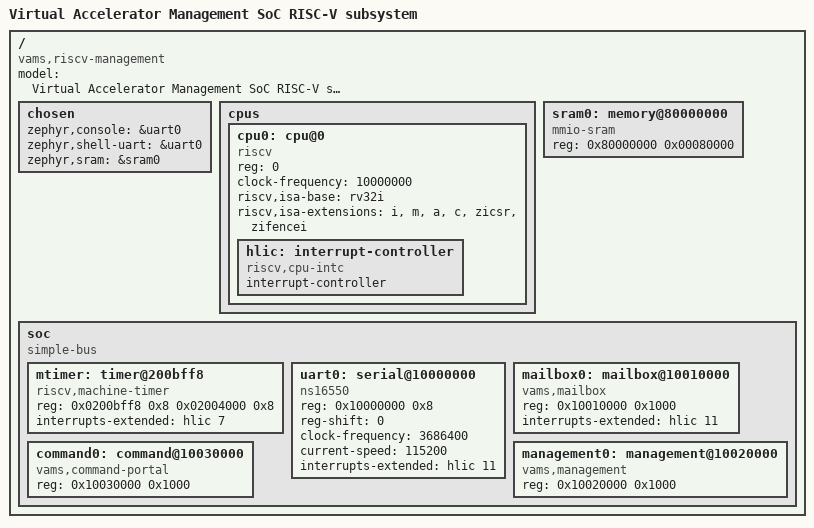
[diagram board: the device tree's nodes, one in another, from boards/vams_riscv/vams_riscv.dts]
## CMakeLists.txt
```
# SPDX-License-Identifier: MIT

cmake_minimum_required(VERSION 3.20.0)
find_package(Zephyr REQUIRED HINTS $ENV{ZEPHYR_BASE})
project(vams_management_firmware)

target_include_directories(app PRIVATE include)
target_sources(app PRIVATE
  src/main.c
  src/command/vams_command.c
  src/health/vams_health.c
  src/logging/vams_event.c
  src/recovery/vams_retained.c
  src/scheduler/vams_scheduler.c
  drivers/vams_command_portal.c
  drivers/vams_mailbox.c
  drivers/vams_management.c
)

# Zephyr's RISC-V linker flow uses OMAGIC for a RAM-only image. Binutils 2.39+
# diagnoses the resulting load segment; the SRAM is intentionally executable
# and writable on this management subsystem.
target_link_options(app PUBLIC -Wl,--no-warn-rwx-segments)
```

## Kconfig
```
# SPDX-License-Identifier: MIT

mainmenu "VAMS management firmware"

source "Kconfig.zephyr"

config VAMS_WATCHDOG_EXPIRY_TEST
	bool "Deliberately allow the first watchdog deadline to expire"
	default n
	help
	  Exercise watchdog recovery by withholding pets until the first
	  watchdog-initiated management reset has completed.

config VAMS_SCHEDULER_TEST_DELAY_MS
	int "Test-only delay before scheduler dispatch"
	default 0
	range 0 1000
	help
	  Delay dispatch to exercise deterministic queued-command expiry. Keep
	  this zero in the normal firmware configuration.

config VAMS_OVERLOAD_TEST
	bool "Inject deterministic diagnostic queue pressure"
	default n
	help
	  Fill the bounded event and heartbeat queues before their consumers
	  start so the overload counters and nonblocking drop policy can be
	  validated. Keep this disabled in the normal firmware configuration.

config VAMS_HEALTH_TEST
	bool "Honor the model's test-only task freeze selector"
	default n
	help
	  Freeze one selected essential task on the first boot so per-task health
	  diagnosis and watchdog recovery can be tested. The selector is ignored
	  in normal firmware builds.
```

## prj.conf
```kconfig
CONFIG_PRINTK=y
CONFIG_BOOT_BANNER=n
CONFIG_COMPILER_WARNINGS_AS_ERRORS=y
CONFIG_ASSERT=y
CONFIG_THREAD_NAME=y
CONFIG_THREAD_STACK_INFO=y
CONFIG_INIT_STACKS=y
CONFIG_STACK_SENTINEL=y
CONFIG_MAIN_STACK_SIZE=1024
CONFIG_ISR_STACK_SIZE=1024
CONFIG_IDLE_STACK_SIZE=512
```

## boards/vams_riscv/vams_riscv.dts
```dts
/* SPDX-License-Identifier: MIT */

/dts-v1/;

/ {
	model = "Virtual Accelerator Management SoC RISC-V subsystem";
	compatible = "vams,riscv-management";
	#address-cells = <1>;
	#size-cells = <1>;

	chosen {
		zephyr,console = &uart0;
		zephyr,shell-uart = &uart0;
		zephyr,sram = &sram0;
	};

	cpus {
		#address-cells = <1>;
		#size-cells = <0>;

		cpu0: cpu@0 {
			compatible = "riscv";
			device_type = "cpu";
			reg = <0>;
			clock-frequency = <10000000>;
			riscv,isa-base = "rv32i";
			riscv,isa-extensions = "i", "m", "a", "c", "zicsr", "zifencei";
			status = "okay";

			hlic: interrupt-controller {
				compatible = "riscv,cpu-intc";
				#address-cells = <0>;
				#interrupt-cells = <1>;
				interrupt-controller;
			};
		};
	};

	sram0: memory@80000000 {
		compatible = "mmio-sram";
		device_type = "memory";
		reg = <0x80000000 0x00080000>;
	};

	soc {
		compatible = "simple-bus";
		#address-cells = <1>;
		#size-cells = <1>;
		ranges;

		mtimer: timer@200bff8 {
			compatible = "riscv,machine-timer";
			reg = <0x0200bff8 0x8 0x02004000 0x8>;
			reg-names = "mtime", "mtimecmp";
			interrupts-extended = <&hlic 7>;
			status = "okay";
		};

		uart0: serial@10000000 {
			compatible = "ns16550";
			reg = <0x10000000 0x8>;
			reg-shift = <0>;
			clock-frequency = <3686400>;
			current-speed = <115200>;
			interrupts-extended = <&hlic 11>;
			status = "okay";
		};

		mailbox0: mailbox@10010000 {
			compatible = "vams,mailbox";
			reg = <0x10010000 0x1000>;
			interrupts-extended = <&hlic 11>;
			status = "okay";
		};

		management0: management@10020000 {
			compatible = "vams,management";
			reg = <0x10020000 0x1000>;
			status = "okay";
		};

		command0: command@10030000 {
			compatible = "vams,command-portal";
			reg = <0x10030000 0x1000>;
			status = "okay";
		};
	};
};
```

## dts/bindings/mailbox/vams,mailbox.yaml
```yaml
description: VAMS host-to-firmware mailbox

compatible: "vams,mailbox"

include: base.yaml

properties:
  reg:
    required: true

  interrupts-extended:
    required: true
```

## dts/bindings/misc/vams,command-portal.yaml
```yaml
description: VAMS private firmware command portal

compatible: "vams,command-portal"

include: base.yaml

properties:
  reg:
    required: true
```

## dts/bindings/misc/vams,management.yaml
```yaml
description: VAMS watchdog, reset, and telemetry registers

compatible: "vams,management"

include: base.yaml

properties:
  reg:
    required: true
```

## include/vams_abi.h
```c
/* SPDX-License-Identifier: MIT */
/* Generated by scripts/gen-vams-abi.py; do not edit. */
#ifndef VAMS_FIRMWARE_ABI_H
#define VAMS_FIRMWARE_ABI_H

#include <stdint.h>

#define VAMS_DESC_VERSION_1 1U
#define VAMS_OP_NOP 0x0000U
#define VAMS_OP_MEM_COPY 0x0001U
#define VAMS_OP_MEM_FILL 0x0002U
#define VAMS_OP_CRC32 0x0003U
#define VAMS_OP_VECTOR_ADD 0x0004U
#define VAMS_SUB_F_VERIFY_CRC 0x0001U
#define VAMS_STATUS_SUCCESS 0x0000U
#define VAMS_STATUS_INVALID 0x0001U
#define VAMS_STATUS_FAILED 0x0002U
#define VAMS_STATUS_TIMED_OUT 0x0003U
#define VAMS_STATUS_CANCELLED 0x0004U
#define VAMS_STATUS_RESET 0x0005U
#define VAMS_ERR_NONE 0x0000U
#define VAMS_ERR_UNSUPPORTED_VERSION 0x0001U
#define VAMS_ERR_INVALID_OPCODE 0x0002U
#define VAMS_ERR_INVALID_FLAGS 0x0003U
#define VAMS_ERR_RESERVED_NONZERO 0x0004U
#define VAMS_ERR_DUPLICATE_ID 0x0005U
#define VAMS_ERR_INVALID_LENGTH 0x0006U
#define VAMS_ERR_INVALID_ALIGNMENT 0x0007U
#define VAMS_ERR_ADDRESS_OVERFLOW 0x0008U
#define VAMS_ERR_INVALID_ADDRESS 0x0009U
#define VAMS_ERR_INVALID_TIMEOUT 0x000aU
#define VAMS_ERR_DMA_READ 0x0010U
#define VAMS_ERR_DMA_WRITE 0x0011U
#define VAMS_ERR_ENGINE 0x0012U
#define VAMS_ERR_TIMEOUT 0x0013U
#define VAMS_ERR_CRC_MISMATCH 0x0014U
#define VAMS_ERR_RESET 0x0015U
#define VAMS_ERR_QUEUE_RESET 0x0016U
#define VAMS_ERR_DEVICE_FATAL 0x0017U

struct __attribute__((packed)) vams_submission {
    uint16_t version;
    uint8_t opcode;
    uint8_t flags;
    uint32_t command_id;
    uint64_t source_dma;
    uint64_t destination_dma;
    uint32_t length;
    uint32_t timeout_ms;
    uint64_t user_cookie;
    uint32_t expected_crc;
    uint32_t reserved0;
    uint64_t reserved1;
    uint64_t reserved2;
};

struct __attribute__((packed)) vams_completion {
    uint32_t command_id;
    uint16_t status;
    uint16_t error_code;
    uint32_t bytes_processed;
    uint32_t result_crc;
    uint64_t user_cookie;
    uint64_t device_timestamp;
};

#define VAMS_SUBMISSION_SIZE 64U
#define VAMS_COMPLETION_SIZE 32U

#endif /* VAMS_FIRMWARE_ABI_H */
```

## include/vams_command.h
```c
/* SPDX-License-Identifier: MIT */
#ifndef VAMS_COMMAND_H
#define VAMS_COMMAND_H

#include <stdint.h>

#include <vams_abi.h>

void vams_command_execute(const struct vams_submission *submission,
			  struct vams_completion *completion,
			  uint64_t timestamp);

#endif /* VAMS_COMMAND_H */
```

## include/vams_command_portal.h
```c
/* SPDX-License-Identifier: MIT */
#ifndef VAMS_COMMAND_PORTAL_H
#define VAMS_COMMAND_PORTAL_H

#include <zephyr/device.h>
#include <zephyr/kernel.h>

#include <vams_abi.h>

bool vams_command_pending(const struct device *dev);
int vams_command_receive(const struct device *dev,
			 struct vams_submission *submission,
			 k_timeout_t timeout);
int vams_command_complete(const struct device *dev,
			  const struct vams_completion *completion);
int vams_command_abort(const struct device *dev,
		       const struct vams_completion *request);
int vams_command_result_receive(const struct device *dev,
				struct vams_completion *result,
				k_timeout_t timeout);

#endif /* VAMS_COMMAND_PORTAL_H */
```

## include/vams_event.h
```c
/* SPDX-License-Identifier: MIT */
#ifndef VAMS_EVENT_H
#define VAMS_EVENT_H

#include <stdint.h>

#include <zephyr/kernel.h>

enum vams_event_id {
	VAMS_EVENT_TRANSITION = 1,
	VAMS_EVENT_PUBLISHED,
	VAMS_EVENT_HEARTBEAT,
	VAMS_EVENT_MAILBOX,
	VAMS_EVENT_ABORT_REQUEST,
	VAMS_EVENT_ABORT_ESCALATED,
	VAMS_EVENT_RESULT_MISMATCH,
	VAMS_EVENT_COMMAND_COMPLETE,
	VAMS_EVENT_TELEMETRY,
	VAMS_EVENT_WATCHDOG_WITHHELD,
	VAMS_EVENT_OVERLOAD_TEST,
	VAMS_EVENT_HEALTH_STUCK,
};

struct vams_event {
	uint64_t timestamp_ms;
	uint64_t value;
	uint32_t command_id;
	uint32_t generation;
	uint32_t arg0;
	uint32_t arg1;
	uint32_t arg2;
	uint16_t id;
	uint16_t reserved;
};

void vams_event_emit(enum vams_event_id id, uint32_t command_id,
		     uint32_t generation, uint32_t arg0, uint32_t arg1,
		     uint32_t arg2, uint64_t value);
int vams_event_receive(struct vams_event *event, k_timeout_t timeout);
uint32_t vams_event_drop_count(void);

#endif /* VAMS_EVENT_H */
```

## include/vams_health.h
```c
/* SPDX-License-Identifier: MIT */
#ifndef VAMS_HEALTH_H
#define VAMS_HEALTH_H

#include <stdbool.h>
#include <stdint.h>

#include <vams_overload.h>

enum vams_health_task_id {
	VAMS_HEALTH_TASK_NONE = 0,
	VAMS_HEALTH_TASK_PRODUCER = 1,
	VAMS_HEALTH_TASK_MONITOR = 2,
	VAMS_HEALTH_TASK_MAILBOX = 3,
	VAMS_HEALTH_TASK_RECEIVER = 4,
	VAMS_HEALTH_TASK_VALIDATOR = 5,
	VAMS_HEALTH_TASK_SCHEDULER = 6,
	VAMS_HEALTH_TASK_RECOVERY = 7,
	VAMS_HEALTH_TASK_COMPLETION = 8,
	VAMS_HEALTH_TASK_COUNT = 8,
};

struct vams_health_tracker {
	uint32_t last_epoch[VAMS_HEALTH_TASK_COUNT];
	uint32_t missed[VAMS_HEALTH_TASK_COUNT];
	uint32_t failure_count;
	uint32_t stuck_task;
	uint32_t startup_grace;
	uint32_t miss_limit;
	bool failure_latched;
};

void vams_health_tracker_init(struct vams_health_tracker *tracker,
			      const uint32_t epochs[VAMS_HEALTH_TASK_COUNT],
			      uint32_t startup_grace, uint32_t miss_limit);
bool vams_health_tracker_update(
	struct vams_health_tracker *tracker,
	const uint32_t epochs[VAMS_HEALTH_TASK_COUNT]);

#endif /* VAMS_HEALTH_H */
```

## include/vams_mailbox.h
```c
/* SPDX-License-Identifier: MIT */

#ifndef VAMS_MAILBOX_H
#define VAMS_MAILBOX_H

#include <stdint.h>

#include <zephyr/device.h>
#include <zephyr/kernel.h>

#define VAMS_MAILBOX_PING UINT32_C(0x00000001)
#define VAMS_MAILBOX_PING_RESPONSE UINT32_C(0x80000001)
#define VAMS_MAILBOX_UNSUPPORTED UINT32_C(0xffffffff)

int vams_mailbox_receive(const struct device *dev, uint32_t *message,
			 k_timeout_t timeout);
int vams_mailbox_respond(const struct device *dev, uint32_t response);

#endif /* VAMS_MAILBOX_H */
```

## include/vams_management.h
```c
/* SPDX-License-Identifier: MIT */

#ifndef VAMS_MANAGEMENT_H
#define VAMS_MANAGEMENT_H

#include <stdbool.h>
#include <stdint.h>

#include <zephyr/device.h>

#define VAMS_MANAGEMENT_RETENTION_SIZE 128U

#define VAMS_RESET_REASON_POWER_ON UINT32_C(0)
#define VAMS_RESET_REASON_FIRMWARE UINT32_C(4)
#define VAMS_RESET_REASON_WATCHDOG UINT32_C(5)

struct vams_management_snapshot {
	uint32_t reset_reason;
	uint32_t watchdog_reset_count;
	uint32_t reset_generation;
	uint32_t reset_notify_count;
	uint32_t reset_notify_fail_count;
	uint32_t reset_ack_count;
	uint32_t reset_ack_timeout_count;
	uint32_t reset_coalesce_count;
	uint32_t test_freeze_task;
	uint32_t mailbox_rx_count;
	uint32_t mailbox_tx_count;
	uint32_t status;
	bool watchdog_enabled;
};

int vams_management_watchdog_start(const struct device *dev,
				   uint32_t timeout_ms);
int vams_management_watchdog_pet(const struct device *dev);
void vams_management_publish(const struct device *dev, uint32_t heartbeat,
			     uint64_t uptime_ms, uint32_t firmware_version);
void vams_management_snapshot(const struct device *dev,
			      struct vams_management_snapshot *snapshot);
void vams_management_reset(const struct device *dev);
void vams_management_retention_read(const struct device *dev, void *data,
				    uint32_t length);
void vams_management_retention_write(const struct device *dev,
				     const void *data, uint32_t length);

#endif /* VAMS_MANAGEMENT_H */
```

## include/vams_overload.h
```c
/* SPDX-License-Identifier: MIT */
#ifndef VAMS_OVERLOAD_H
#define VAMS_OVERLOAD_H

#include <stdbool.h>
#include <stdint.h>

static inline uint32_t vams_counter_increment(uint32_t value)
{
	return value == UINT32_MAX ? UINT32_MAX : value + 1U;
}

static inline bool vams_command_admission_allowed(bool portal_pending,
						   uint32_t pool_free)
{
	return portal_pending && pool_free > 0U;
}

#endif /* VAMS_OVERLOAD_H */
```

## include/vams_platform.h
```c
/* SPDX-License-Identifier: MIT */
#ifndef VAMS_PLATFORM_H
#define VAMS_PLATFORM_H

#ifndef __ASSEMBLER__
#include <stdint.h>
#define VAMS_U32(value) UINT32_C(value)
#define VAMS_U8(value)  UINT8_C(value)
#else
#define VAMS_U32(value) value
#define VAMS_U8(value)  value
#endif

#define VAMS_ROM_BASE             VAMS_U32(0x00001000)
#define VAMS_ROM_SIZE             VAMS_U32(0x00010000)
#define VAMS_ACLINT_SWI_BASE      VAMS_U32(0x02000000)
#define VAMS_ACLINT_MTIMER_BASE   VAMS_U32(0x02004000)
#define VAMS_ACLINT_MTIMECMP      (VAMS_ACLINT_MTIMER_BASE + VAMS_U32(0x0000))
#define VAMS_ACLINT_MTIME         (VAMS_ACLINT_MTIMER_BASE + VAMS_U32(0x7ff8))
#define VAMS_UART_BASE            VAMS_U32(0x10000000)
#define VAMS_SRAM_BASE            VAMS_U32(0x80000000)
#define VAMS_SRAM_SIZE            VAMS_U32(0x00080000)

#define VAMS_UART_THR             VAMS_U32(0x0)
#define VAMS_UART_LSR             VAMS_U32(0x5)
#define VAMS_UART_LSR_THRE        VAMS_U8(0x20)

#define VAMS_MCAUSE_TIMER         VAMS_U32(0x80000007)
#define VAMS_MIE_MTIE             (VAMS_U32(1) << 7)
#define VAMS_MSTATUS_MIE          (VAMS_U32(1) << 3)

#endif
```

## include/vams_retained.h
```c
/* SPDX-License-Identifier: MIT */
#ifndef VAMS_RETAINED_H
#define VAMS_RETAINED_H

#include <stdbool.h>
#include <stdint.h>

#define VAMS_RETAINED_MAGIC UINT32_C(0x56414d52)
#define VAMS_RETAINED_VERSION 1U
#define VAMS_RETAINED_EVENT_COUNT 4U

struct vams_retained_event {
	uint32_t event_id;
	uint32_t command_id;
	uint32_t generation;
	uint32_t timestamp_ms;
};

struct vams_retained_record {
	uint32_t magic;
	uint16_t version;
	uint16_t length;
	uint32_t crc32;
	uint32_t boot_count;
	uint32_t reset_reason;
	uint32_t reset_generation;
	uint32_t last_stuck_task;
	uint32_t health_failure_count;
	uint32_t last_command_id;
	uint32_t last_command_generation;
	uint32_t last_assertion;
	uint32_t stack_failure;
	uint32_t event_head;
	uint32_t event_count;
	struct vams_retained_event events[VAMS_RETAINED_EVENT_COUNT];
};

uint32_t vams_retained_crc32(const struct vams_retained_record *record);
bool vams_retained_validate(const struct vams_retained_record *record);
void vams_retained_format(struct vams_retained_record *record,
			  uint32_t reset_reason, uint32_t generation);

#ifdef __ZEPHYR__
#include <zephyr/device.h>
bool vams_retained_boot(const struct device *management, uint32_t reset_reason,
			uint32_t generation);
void vams_retained_snapshot(struct vams_retained_record *record);
void vams_retained_note_health(uint32_t stuck_task, uint32_t failures);
void vams_retained_note_command(uint32_t command_id, uint32_t generation);
void vams_retained_clear_command(void);
void vams_retained_note_event(uint32_t event_id, uint32_t command_id,
			      uint32_t generation, uint32_t timestamp_ms);
#endif

#endif /* VAMS_RETAINED_H */
```

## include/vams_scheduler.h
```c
/* SPDX-License-Identifier: MIT */
#ifndef VAMS_SCHEDULER_H
#define VAMS_SCHEDULER_H

#include <stdbool.h>
#include <stdint.h>

#include <vams_abi.h>

#define VAMS_COMMAND_POOL_SIZE 8U

enum vams_command_state {
	VAMS_COMMAND_FREE = 0,
	VAMS_COMMAND_SUBMITTED = 1,
	VAMS_COMMAND_VALIDATING = 2,
	VAMS_COMMAND_QUEUED = 3,
	VAMS_COMMAND_RUNNING = 4,
	VAMS_COMMAND_ABORTING = 5,
	VAMS_COMMAND_COMPLETED = 6,
	VAMS_COMMAND_COMPLETED_ERROR = 7,
	VAMS_COMMAND_CANCELLED = 8,
};

struct vams_command_object {
	struct vams_submission submission;
	struct vams_completion completion;
	uint64_t captured_at_ms;
	uint64_t deadline_ms;
	uint32_t generation;
	uint32_t sequence;
	uint8_t state;
	uint8_t publication_count;
	uint8_t reserved[2];
};

void vams_scheduler_capture(struct vams_command_object *command,
			    uint32_t generation, uint32_t sequence,
			    uint64_t captured_at_ms);
void vams_scheduler_transition(struct vams_command_object *command,
			       enum vams_command_state expected,
			       enum vams_command_state next);
bool vams_scheduler_deadline_expired(const struct vams_command_object *command,
				     uint64_t now_ms);
static inline bool vams_scheduler_precedes(
	const struct vams_command_object *first,
	const struct vams_command_object *second)
{
	return first->deadline_ms < second->deadline_ms ||
	       (first->deadline_ms == second->deadline_ms &&
		first->sequence < second->sequence);
}
void vams_scheduler_timeout(struct vams_command_object *command,
			    uint64_t timestamp_ms);
void vams_scheduler_cancel(struct vams_command_object *command,
			   uint64_t timestamp_ms);
int vams_scheduler_apply_result(struct vams_command_object *command,
				const struct vams_completion *result);
void vams_scheduler_begin_abort(struct vams_command_object *command,
				uint64_t timestamp_ms);
void vams_scheduler_escalate(struct vams_command_object *command,
			     uint64_t timestamp_ms);
void vams_scheduler_mark_published(struct vams_command_object *command);

#endif /* VAMS_SCHEDULER_H */
```
